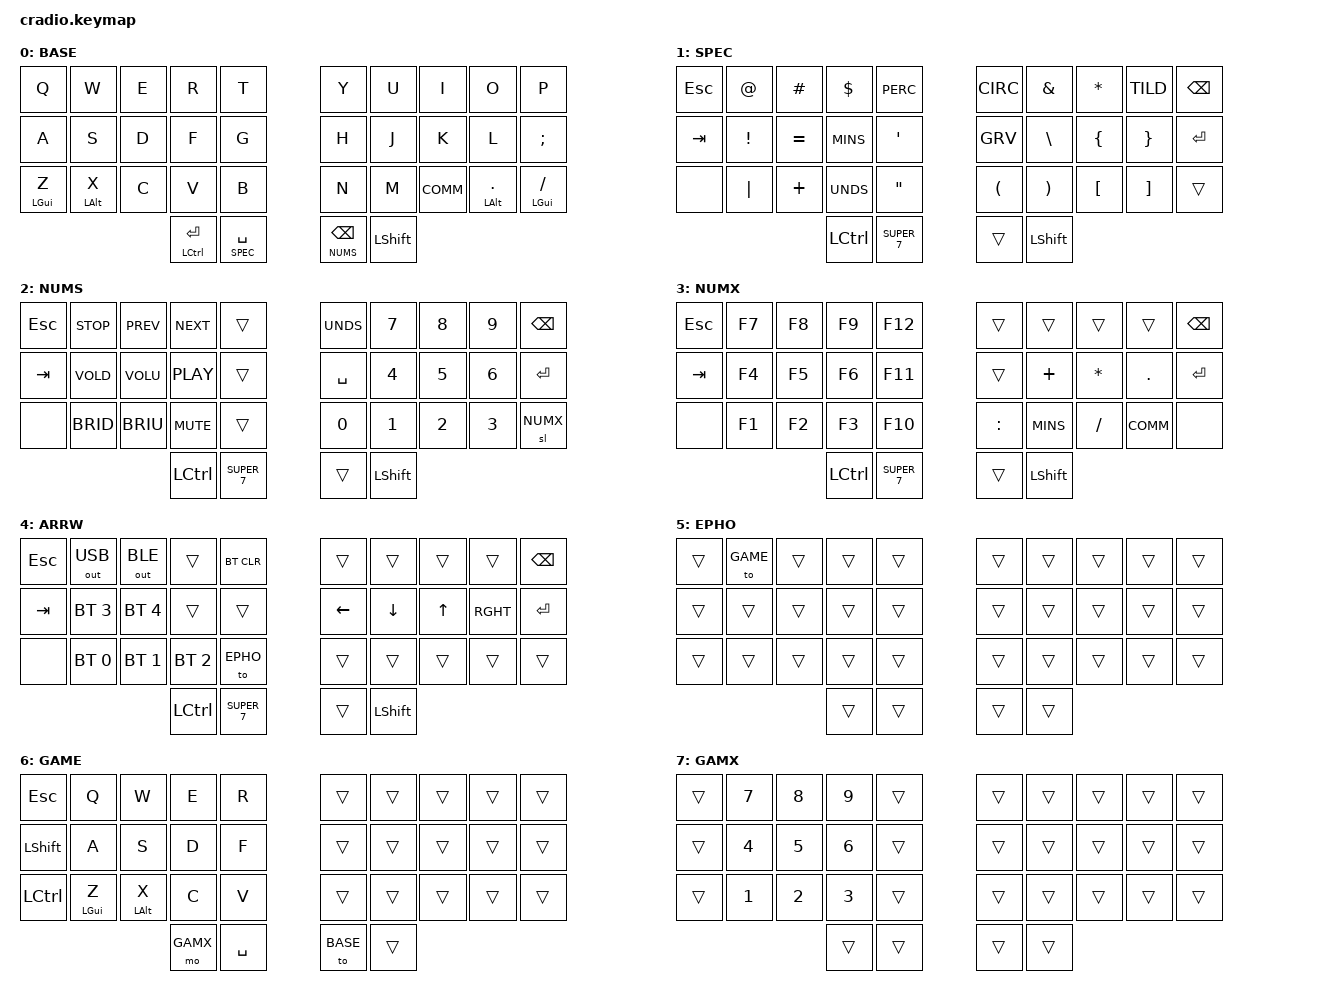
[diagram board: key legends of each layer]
/*
 * Copyright (c) 2020 The ZMK Contributors
 * Copyright (c) 2022 Chris Milson-Tokunaga
 *
 * SPDX-License-Identifier: MIT
 */

#include <behaviors.dtsi>
#include <dt-bindings/zmk/keys.h>
#include <dt-bindings/zmk/bt.h>
#include <dt-bindings/zmk/outputs.h>

// 4 or fewer character keycode aliases to keep the layouts nice
#undef COMM
#define COMM COMMA
#undef PERC
#define PERC PERCENT
#undef CIRC
#define CIRC CARET
#undef TILD
#define TILD TILDE
#undef EQL
#define EQL EQUAL
#undef MINS
#define MINS MINUS
#undef GRV
#define GRV GRAVE
#undef UNDS
#define UNDS UNDERSCORE
#undef RGHT 
#define RGHT RIGHT
#undef SPC
#define SPC SPACE
#undef STOP
#define STOP C_STOP
#undef PREV 
#define PREV C_PREVIOUS
#undef NEXT
#define NEXT C_NEXT
#undef VOLU 
#define VOLU C_VOLUME_UP
#undef VOLD 
#define VOLD C_VOLUME_DOWN
#undef PLAY
#define PLAY C_PLAY_PAUSE
#undef BRIU
#define BRIU C_BRIGHTNESS_INC
#undef BRID
#define BRID C_BRIGHTNESS_DEC
#undef MUTE
#define MUTE C_MUTE

#define BT_CLEAR &bt BT_CLR
#define BT_0 &bt BT_SEL 0
#define BT_1 &bt BT_SEL 1
#define BT_2 &bt BT_SEL 2
#define BT_3 &bt BT_SEL 3
#define BT_4 &bt BT_SEL 4
#define USE_USB &out OUT_USB
#define USE_BLE &out OUT_BLE

// Unobtrusive trans
#define ________ &trans

#define SUPER_1 &kp ESCAPE
#define SUPER_2 &kp TAB
// Was KC_BTN1 on qmk keymap, but not supported in stock zmk yet.
#define SUPER_3 &none
#define SUPER_4 &kp BACKSPACE
#define SUPER_5 &kp ENTER
#define SUPER_6 &kp LCTRL
#define SUPER_7 ________
#define SUPER_8 &kp LSHFT

// layer aliases
#define BASE 0
#define SPEC 1
#define NUMS 2
#define NUMX 3
#define ARRW 4
#define EPHO 5
#define GAME 6
#define GAMX 7

#define GUI_FSLH &mt LGUI FSLH
#define GUI_Z &mt LGUI Z
#define ALT_X &mt LALT X
#define ALT_DOT &mt LALT DOT

&sl {
  release-after-ms = <2000>;
};

/ {
//  behaviors {
//    tomo: behaviour_tomo {
//      compatible = "zmk,behaviour-hold-tap";
//      label = "to_mo";
//      #binding-cells = <2>;
//      flavor = "balanced";
//      tapping-term-ms = <200>;
//      bindings = <&to>, <&mo>;
//    }
//  };

  conditional_layers {
    compatible = "zmk,conditional-layers"; 
    tri_layer {
      if-layers = <SPEC NUMS>;
      then-layer = <ARRW>;
    };
  };

  keymap {
    compatible = "zmk,keymap";

    base_layer {
      display-name = "BASE";
      bindings = <
        &kp Q    &kp W    &kp E    &kp R    &kp T              &kp Y    &kp U    &kp I    &kp O    &kp P
        &kp A    &kp S    &kp D    &kp F    &kp G              &kp H    &kp J    &kp K    &kp L    &kp SEMI
        GUI_Z    ALT_X    &kp C    &kp V    &kp B              &kp N    &kp M    &kp COMM ALT_DOT  GUI_FSLH
                             &mt LCTL ENTER &lt SPEC SPC       &lt NUMS BSPC &kp LSHFT
      >;
    };

    special_layer {
      display-name = "SPEC";
      bindings = <
        SUPER_1  &kp AT   &kp HASH &kp DLLR &kp PERC           &kp CIRC &kp AMPS &kp STAR &kp TILD SUPER_4 
        SUPER_2  &kp EXCL &kp EQL  &kp MINS &kp APOS           &kp GRV  &kp BSLH &kp LBRC &kp RBRC SUPER_5 
        SUPER_3  &kp PIPE &kp PLUS &kp UNDS &kp DQT            &kp LPAR &kp RPAR &kp LBKT &kp RBKT ________
                                   SUPER_6  SUPER_7            ________ SUPER_8
      >;
    };

    number_layer {
      display-name = "NUMS";
      bindings = <
        SUPER_1  &kp STOP &kp PREV &kp NEXT ________           &kp UNDS &kp N7   &kp N8   &kp N9   SUPER_4 
        SUPER_2  &kp VOLD &kp VOLU &kp PLAY ________           &kp SPC  &kp N4   &kp N5   &kp N6   SUPER_5 
        SUPER_3  &kp BRID &kp BRIU &kp MUTE ________           &kp N0   &kp N1   &kp N2   &kp N3   &sl NUMX 
                                   SUPER_6  SUPER_7            ________ SUPER_8
      >;
    };

    number_aux_layer {
      display-name = "NUMX";
      bindings = <
        SUPER_1  &kp F7   &kp F8   &kp F9   &kp F12            ________ ________ ________ ________ SUPER_4 
        SUPER_2  &kp F4   &kp F5   &kp F6   &kp F11            ________ &kp PLUS &kp STAR &kp DOT  SUPER_5 
        SUPER_3  &kp F1   &kp F2   &kp F3   &kp F10            &kp COLN &kp MINS &kp FSLH &kp COMM &none
                                   SUPER_6  SUPER_7            ________ SUPER_8
      >;
    };

    arrow_layer {
      display-name = "ARRW";
      // Left hand contained mouse control - not supported in stock zmk yet.
      bindings = <
        SUPER_1  USE_USB  USE_BLE  ________ BT_CLEAR           ________ ________ ________ ________ SUPER_4 
        SUPER_2  BT_3     BT_4     ________ ________           &kp LEFT &kp DOWN &kp UP   &kp RGHT SUPER_5 
        SUPER_3  BT_0     BT_1     BT_2     &to EPHO           ________ ________ ________ ________ ________
                                   SUPER_6  SUPER_7            ________ SUPER_8
      >;
    };

    ephemeral_home {
      display-name = "EPHO";
      // Layer to link to seldom-used layers.
      bindings = <
        ________ &to GAME ________ ________ ________           ________ ________ ________ ________ ________ 
        ________ ________ ________ ________ ________           ________ ________ ________ ________ ________ 
        ________ ________ ________ ________ ________           ________ ________ ________ ________ ________ 
                                   ________ ________           ________ ________ 
      >;
    };
    
    game_layer {
      display-name = "GAME";
      bindings = <
        SUPER_1  &kp Q    &kp W    &kp E    &kp R              ________ ________ ________ ________ ________ 
        SUPER_8  &kp A    &kp S    &kp D    &kp F              ________ ________ ________ ________ ________ 
        SUPER_6  GUI_Z    ALT_X    &kp C    &kp V              ________ ________ ________ ________ ________ 
                               &mo GAMX &kp SPACE              &to BASE ________
      >;
    };
    
    game_aux_layer {
      display-name = "GAMX";
      bindings = <
        ________ &kp N7   &kp N8   &kp N9   ________           ________ ________ ________ ________ ________ 
        ________ &kp N4   &kp N5   &kp N6   ________           ________ ________ ________ ________ ________ 
        ________ &kp N1   &kp N2   &kp N3   ________           ________ ________ ________ ________ ________ 
                                   ________ ________           ________ ________ 
      >;
    };
  };
};
